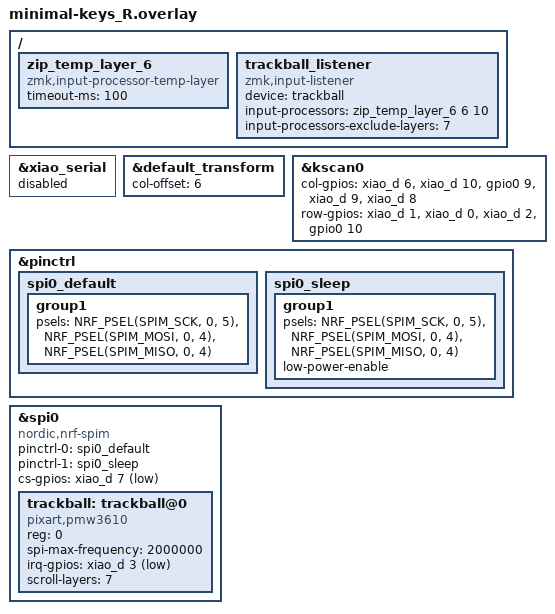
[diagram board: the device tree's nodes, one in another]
#include "minimal-keys.dtsi"

&xiao_serial { status = "disabled"; };

&default_transform {
    col-offset = <6>;
};

/* 1. トラックボール動作設定：オートマウスのみ定義 */
/ {
    zip_temp_layer_6: zip_temp_layer_6 {
        compatible = "zmk,input-processor-temp-layer";
        #input-processor-cells = <2>;
　　　　timeout-ms = <100>;
    };

    trackball_listener {
        compatible = "zmk,input-listener";
        device = <&trackball>;
        input-processors = <&zip_temp_layer_6 6 10>;
　　　　input-processors-exclude-layers = <7>;
    };
};

/* 2. キーマトリックス設定 */
&kscan0 {
    col-gpios
        = <&xiao_d 6 GPIO_ACTIVE_HIGH>
        , <&xiao_d 10 GPIO_ACTIVE_HIGH>
        , <&gpio0 9 GPIO_ACTIVE_HIGH>
        , <&xiao_d 9 GPIO_ACTIVE_HIGH>
        , <&xiao_d 8 GPIO_ACTIVE_HIGH>
        ;
    row-gpios 
        = <&xiao_d 1 (GPIO_ACTIVE_HIGH | GPIO_PULL_DOWN)>
        , <&xiao_d 0 (GPIO_ACTIVE_HIGH | GPIO_PULL_DOWN)>
        , <&xiao_d 2 (GPIO_ACTIVE_HIGH | GPIO_PULL_DOWN)>
        , <&gpio0 10 (GPIO_ACTIVE_HIGH | GPIO_PULL_DOWN)>
        ;
};

/* 3. SPIピン設定 */
&pinctrl {
    spi0_default: spi0_default {
        group1 {
            psels = <NRF_PSEL(SPIM_SCK, 0, 5)>,
                <NRF_PSEL(SPIM_MOSI, 0, 4)>,
                <NRF_PSEL(SPIM_MISO, 0, 4)>;
        };
    };

    spi0_sleep: spi0_sleep {
        group1 {
            psels = <NRF_PSEL(SPIM_SCK, 0, 5)>,
                <NRF_PSEL(SPIM_MOSI, 0, 4)>,
                <NRF_PSEL(SPIM_MISO, 0, 4)>;
            low-power-enable;
        };
    };
};

/* 4. SPIバスとトラックボール本体 */
&spi0 {
    status = "okay";
    compatible = "nordic,nrf-spim";
    pinctrl-0 = <&spi0_default>;
    pinctrl-1 = <&spi0_sleep>;
    pinctrl-names = "default", "sleep";
    cs-gpios = <&xiao_d 7 GPIO_ACTIVE_LOW>;

    trackball: trackball@0 {
        status = "okay";
        compatible = "pixart,pmw3610";
        reg = <0>;
        spi-max-frequency = <2000000>;
        irq-gpios = <&xiao_d 3 (GPIO_ACTIVE_LOW | GPIO_PULL_UP)>;
        
        /* ドライバの標準機能：レイヤー3にいる間だけスクロールにする */
        /* これを 6 に含めなければ、オートマウス中に勝手にスクロールすることはありません */
        scroll-layers = <7>; 
    };
};
